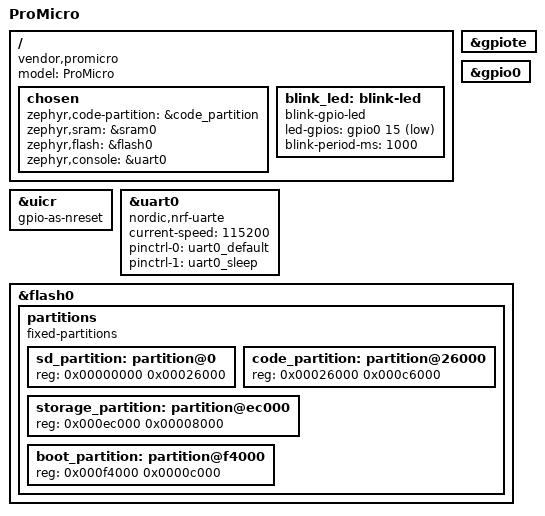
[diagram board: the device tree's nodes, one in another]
/*
 * Copyright (c) 2021 Nordic Semiconductor ASA
 * SPDX-License-Identifier: Apache-2.0
 */

/dts-v1/;
#include <nordic/nrf52840_qiaa.dtsi>
#include "promicro-pinctrl.dtsi"

/ {
	model = "ProMicro";
	compatible = "vendor,promicro";

	chosen {
        zephyr,code-partition = &code_partition;
        zephyr,sram = &sram0;
        zephyr,flash = &flash0;
		zephyr,console = &uart0;
	};

	blink_led: blink-led {
		compatible = "blink-gpio-led";
		led-gpios = <&gpio0 15 GPIO_ACTIVE_LOW>;
		blink-period-ms = <1000>;
	};
};

&uicr {
	gpio-as-nreset;
};

&gpiote {
	status = "okay";
};

&gpio0 {
	status = "okay";
};

&uart0 {
	compatible = "nordic,nrf-uarte";
	status = "okay";

	current-speed = <115200>;
	pinctrl-0 = <&uart0_default>;
	pinctrl-1 = <&uart0_sleep>;
	pinctrl-names = "default", "sleep";
};

&flash0 {
    /*
     * For more information, see:
     * http://docs.zephyrproject.org/latest/devices/dts/flash_partitions.html
     */
    partitions {
        compatible = "fixed-partitions";
        #address-cells = <1>;
        #size-cells = <1>;

        sd_partition: partition@0 {
            reg = <0x00000000 0x00026000>;
        };
        code_partition: partition@26000 {
            reg = <0x00026000 0x000c6000>;
        };

        /*
         * The flash starting at 0x000ec000 and ending at
         * 0x000f3fff is reserved for use by the application.
         */

        /*
         * Storage partition will be used by FCB/LittleFS/NVS
         * if enabled.
         */
        storage_partition: partition@ec000 {
            reg = <0x000ec000 0x00008000>;
        };

        boot_partition: partition@f4000 {
            reg = <0x000f4000 0x0000c000>;
        };
    };
};
